VERSION "HIPBNYYYYYYYYYYYYYYYYYYYYYYYYYYYYYYYYYYYYY/4/%%%/4/'%**4YYY///"

NS_ :

BS_:

BU_: PDM WHEEL COOLANT SHUTDOWN ETC VCU SUSPENSION

BO_ 624 PDM_Current: 8 PDM
 SG_ Unreg_Amps : 0|32@1- (0.001,0) [0|0] "A" Vector__XXX
 SG_ FiveVolt_Amps : 32|32@1- (0.001,0) [0|0] "A" Vector__XXX

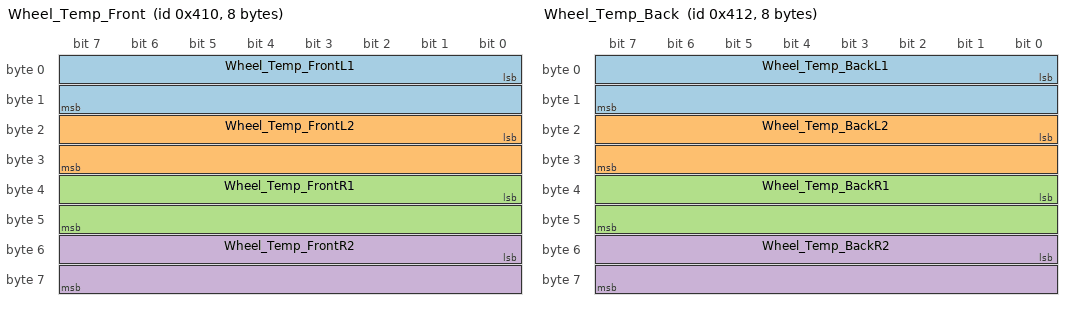
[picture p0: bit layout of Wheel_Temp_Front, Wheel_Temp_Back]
BO_ 1040 Wheel_Temp_Front: 8 WHEEL
 SG_ Wheel_Temp_FrontL1 : 0|16@1- (0.01,0) [0|0] "Â°C" Vector__XXX
 SG_ Wheel_Temp_FrontL2 : 16|16@1- (0.01,0) [0|0] "Â°C" Vector__XXX
 SG_ Wheel_Temp_FrontR1 : 32|16@1- (0.01,0) [0|0] "Â°C" Vector__XXX
 SG_ Wheel_Temp_FrontR2 : 48|16@1- (0.01,0) [0|0] "Â°C" Vector__XXX

BO_ 1041 Wheel_Speed_Front: 4 WHEEL
 SG_ Wheel_Speed_FrontL : 0|16@1- (0.01,0) [0|0] "rot/s" Vector__XXX
 SG_ Wheel_Speed_FrontR : 16|16@1- (0.01,0) [0|0] "rot/s" Vector__XXX

BO_ 1042 Wheel_Temp_Back: 8 WHEEL
 SG_ Wheel_Temp_BackL1 : 0|16@1- (0.01,0) [0|0] "Â°C" Vector__XXX
 SG_ Wheel_Temp_BackL2 : 16|16@1- (0.01,0) [0|0] "Â°C" Vector__XXX
 SG_ Wheel_Temp_BackR1 : 32|16@1- (0.01,0) [0|0] "Â°C" Vector__XXX
 SG_ Wheel_Temp_BackR2 : 48|16@1- (0.01,0) [0|0] "Â°C" Vector__XXX

BO_ 1056 Coolant_Flow_Message: 8 COOLANT
 SG_ Coolant_Temp : 0|32@1- (1,-40) [0|0] "Â°C" Vector__XXX
 SG_ Coolant_Flow : 0|32@1- (1,0) [0|0] "mL/s" Vector__XXX

BO_ 784 Shutdown_Status: 1 SHUTDOWN
 SG_ Voltage_Sag : 0|8@1- (1,0) [0|0] "bitset, lsbit is shutdown 1, support from 1-6" Vector__XXX

BO_ 16 Brake_tx: 4 ETC

BO_ 0 Drive_Status: 1 VCU

BO_ 1312 Sus_Pots: 4 SUSPENSION
 SG_ Sus_Front : 0|16@1- (1,0) [16|16] "cm" Vector__XXX
 SG_ Sus_Back : 0|16@1- (1,0) [16|16] "cm" Vector__XXX

CM_ SG_ 624 Unreg_Amps "100";
CM_ SG_ 624 FiveVolt_Amps "100";
CM_ SG_ 1040 Wheel_Temp_FrontL1 "100";
CM_ SG_ 1040 Wheel_Temp_FrontL2 "100";
CM_ SG_ 1040 Wheel_Temp_FrontR1 "100";
CM_ SG_ 1040 Wheel_Temp_FrontR2 "100";
CM_ SG_ 1041 Wheel_Speed_FrontL "100";
CM_ SG_ 1041 Wheel_Speed_FrontR "100";
CM_ SG_ 1042 Wheel_Temp_BackL1 "100";
CM_ SG_ 1042 Wheel_Temp_BackL2 "100";
CM_ SG_ 1042 Wheel_Temp_BackR1 "100";
CM_ SG_ 1042 Wheel_Temp_BackR2 "100";
CM_ SG_ 1056 Coolant_Temp "100";
CM_ SG_ 1056 Coolant_Flow "500";
CM_ SG_ 784 Voltage_Sag "1000";
CM_ SG_ 1312 Sus_Front "100?";
BA_DEF_  "BusType" STRING ;
BA_DEF_DEF_  "BusType" "";
BA_ "BusType" "CAN";
SIG_VALTYPE_ 624 Unreg_Amps : 1;
SIG_VALTYPE_ 624 FiveVolt_Amps : 1;
SIG_VALTYPE_ 1040 Wheel_Temp_FrontL1 : 1;
SIG_VALTYPE_ 1040 Wheel_Temp_FrontL2 : 1;
SIG_VALTYPE_ 1040 Wheel_Temp_FrontR1 : 1;
SIG_VALTYPE_ 1040 Wheel_Temp_FrontR2 : 1;
SIG_VALTYPE_ 1041 Wheel_Speed_FrontL : 1;
SIG_VALTYPE_ 1041 Wheel_Speed_FrontR : 1;
SIG_VALTYPE_ 1042 Wheel_Temp_BackL1 : 1;
SIG_VALTYPE_ 1042 Wheel_Temp_BackL2 : 1;
SIG_VALTYPE_ 1042 Wheel_Temp_BackR1 : 1;
SIG_VALTYPE_ 1042 Wheel_Temp_BackR2 : 1;
SIG_VALTYPE_ 1056 Coolant_Temp : 1;
SIG_VALTYPE_ 1056 Coolant_Flow : 1;
SIG_VALTYPE_ 784 Voltage_Sag : 1;
SIG_VALTYPE_ 1312 Sus_Front : 1;
SIG_VALTYPE_ 1312 Sus_Back : 1;
